# ESP32 register map
Vendor: ESPRESSIF SYSTEMS (SHANGHAI) CO., LTD.; Series: ESP32 Series; File version: 17
CPU: Xtensa LX6 r0p0, little endian, no MPU, FPU, 0 interrupt priority bits
Address unit: 32 bits
Registers are 32-bit, read-write, reset 0x0 unless marked. A register's access mark holds for its fields unless they carry their own. Offsets are from the block's base; [hi:lo] are bit positions; {n}, {i} and the like mark numbered series.

## AES — AES (Advanced Encryption Standard) Accelerator
Base 0x3FF01000
0x00 START wo
  [0] START — Write 1 to start the AES operation.
0x04 IDLE ro
  [0] IDLE — AES Idle register. Reads ’zero’ while the AES Accelerator is busy processing; reads ’one’ otherwise.
0x08 MODE
  [7:0] MODE — Selects the AES accelerator mode of operation. See Table 22-1 for details.
{0x10+4i} KEY[{i}] (i=0..7)
  [7:0] KEY — AES key material register.
{0x30+4i} TEXT[{i}] (i=0..3)
  [7:0] TEXT — Plaintext and ciphertext register.
0x40 ENDIAN
  [1:0] ENDIAN — Endianness selection register. See Table 22-2 for details.

## APB_CTRL — APB (Advanced Peripheral Bus) Controller
Base 0x3FF66000
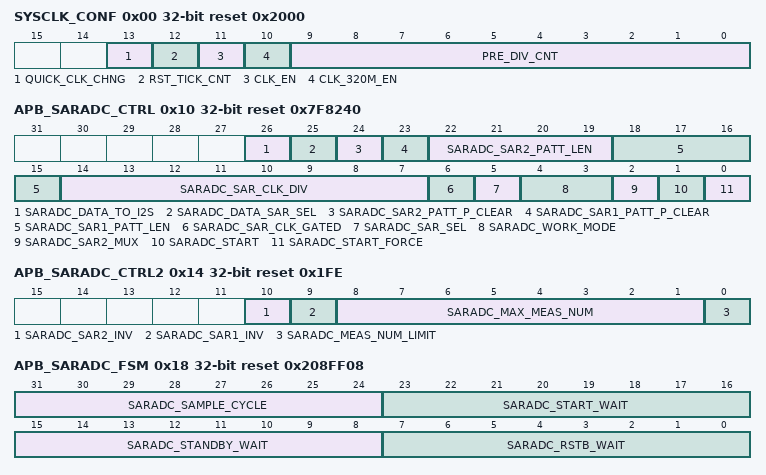
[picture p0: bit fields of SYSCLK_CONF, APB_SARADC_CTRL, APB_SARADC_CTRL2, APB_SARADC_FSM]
0x00 SYSCLK_CONF reset 0x2000
  [13] QUICK_CLK_CHNG, [12] RST_TICK_CNT, [11] CLK_EN, [10] CLK_320M_EN, [9:0] PRE_DIV_CNT
0x04 XTAL_TICK_CONF reset 0x27
  [7:0] XTAL_TICK_NUM
0x08 PLL_TICK_CONF reset 0x4F
  [7:0] PLL_TICK_NUM
0x0C CK8M_TICK_CONF reset 0xB
  [7:0] CK8M_TICK_NUM
0x10 APB_SARADC_CTRL reset 0x7F8240
  [26] SARADC_DATA_TO_I2S — 1: I2S input data is from SAR ADC (for DMA) 0: I2S input data is from GPIO matrix
  [25] SARADC_DATA_SAR_SEL — 1: sar_sel will be coded by the MSB of the 16-bit output data in this case the resolution should not be larger than 11 bits.
  [24] SARADC_SAR2_PATT_P_CLEAR — clear the pointer of pattern table for DIG ADC2 CTRL
  [23] SARADC_SAR1_PATT_P_CLEAR — clear the pointer of pattern table for DIG ADC1 CTRL
  [22:19] SARADC_SAR2_PATT_LEN — 0 ~ 15 means length 1 ~ 16
  [18:15] SARADC_SAR1_PATT_LEN — 0 ~ 15 means length 1 ~ 16
  [14:7] SARADC_SAR_CLK_DIV — SAR clock divider
  [6] SARADC_SAR_CLK_GATED
  [5] SARADC_SAR_SEL — 0: SAR1 1: SAR2 only work for single SAR mode
  [4:3] SARADC_WORK_MODE — 0: single mode 1: double mode 2: alternate mode
  [2] SARADC_SAR2_MUX — 1: SAR ADC2 is controlled by DIG ADC2 CTRL 0: SAR ADC2 is controlled by PWDET CTRL
  [1] SARADC_START
  [0] SARADC_START_FORCE
0x14 APB_SARADC_CTRL2 reset 0x1FE
  [10] SARADC_SAR2_INV — 1: data to DIG ADC2 CTRL is inverted otherwise not
  [9] SARADC_SAR1_INV — 1: data to DIG ADC1 CTRL is inverted otherwise not
  [8:1] SARADC_MAX_MEAS_NUM — max conversion number
  [0] SARADC_MEAS_NUM_LIMIT
0x18 APB_SARADC_FSM reset 0x208FF08
  [31:24] SARADC_SAMPLE_CYCLE — sample cycles
  [23:16] SARADC_START_WAIT
  [15:8] SARADC_STANDBY_WAIT
  [7:0] SARADC_RSTB_WAIT
0x1C APB_SARADC_SAR1_PATT_TAB1 reset 0xF0F0F0F
  [31:0] SARADC_SAR1_PATT_TAB1 — item 0 ~ 3 for pattern table 1 (each item one byte)
{0x18+4i} APB_SARADC_SAR1_PATT_TAB{i} reset 0xF0F0F0F (i=2..4)
  [31:0] SARADC_SAR1_PATT_TAB{i} — Item {4i-4} ~ {4i-1} for pattern table 1 (each item one byte)
0x2C APB_SARADC_SAR2_PATT_TAB1 reset 0xF0F0F0F
  [31:0] SARADC_SAR2_PATT_TAB1 — item 0 ~ 3 for pattern table 2 (each item one byte)
{0x28+4i} APB_SARADC_SAR2_PATT_TAB{i} reset 0xF0F0F0F (i=2..4)
  [31:0] SARADC_SAR2_PATT_TAB{i} — Item {4i-4} ~ {4i-1} for pattern table 2 (each item one byte)
0x3C APLL_TICK_CONF reset 0x63
  [7:0] APLL_TICK_NUM
0x7C DATE reset 0x16042000

## BB — BB Peripheral
Base 0x3FF5D000
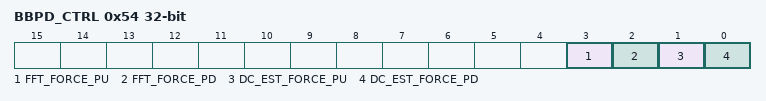
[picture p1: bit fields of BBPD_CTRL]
0x54 BBPD_CTRL — Baseband control register
  [3] FFT_FORCE_PU, [2] FFT_FORCE_PD, [1] DC_EST_FORCE_PU, [0] DC_EST_FORCE_PD

## EMAC_EXT — Ethernet Clock, PHY type, and SRAM configuration registers
Base 0x3FF69800
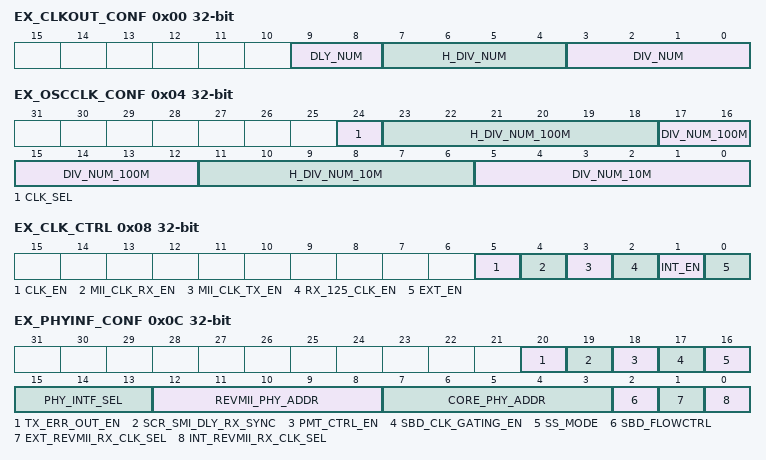
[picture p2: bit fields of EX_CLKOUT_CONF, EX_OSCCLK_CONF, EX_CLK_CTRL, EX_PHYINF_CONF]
0x00 EX_CLKOUT_CONF
  [9:8] DLY_NUM, [7:4] H_DIV_NUM, [3:0] DIV_NUM
0x04 EX_OSCCLK_CONF
  [24] CLK_SEL, [23:18] H_DIV_NUM_100M, [17:12] DIV_NUM_100M, [11:6] H_DIV_NUM_10M, [5:0] DIV_NUM_10M
0x08 EX_CLK_CTRL
  [5] CLK_EN, [4] MII_CLK_RX_EN, [3] MII_CLK_TX_EN, [2] RX_125_CLK_EN, [1] INT_EN, [0] EXT_EN
0x0C EX_PHYINF_CONF
  [20] TX_ERR_OUT_EN, [19] SCR_SMI_DLY_RX_SYNC, [18] PMT_CTRL_EN, [17] SBD_CLK_GATING_EN, [16] SS_MODE, [15:13] PHY_INTF_SEL, [12:8] REVMII_PHY_ADDR, [7:3] CORE_PHY_ADDR, [2] SBD_FLOWCTRL, [1] EXT_REVMII_RX_CLK_SEL, [0] INT_REVMII_RX_CLK_SEL
0x10 PD_SEL
  [1:0] RAM_PD_EN
0xFC EX_DATE access not given
